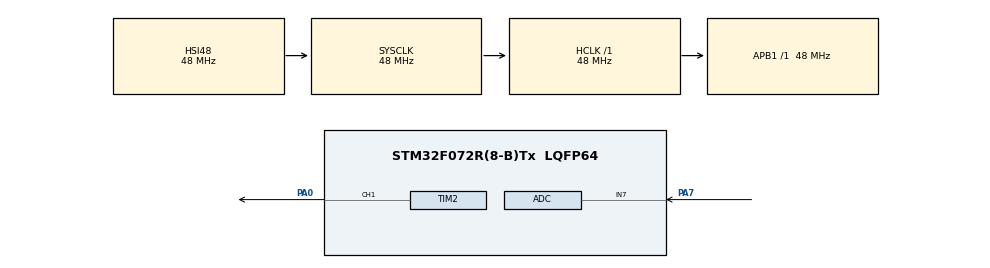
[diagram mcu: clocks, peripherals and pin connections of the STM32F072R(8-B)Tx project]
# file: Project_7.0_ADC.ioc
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ADC.SamplingTime=ADC_SAMPLETIME_1CYCLE_5
Dma.ADC.0.Direction=DMA_PERIPH_TO_MEMORY
Dma.ADC.0.Instance=DMA1_Channel1
Dma.ADC.0.MemDataAlignment=DMA_MDATAALIGN_HALFWORD
Dma.ADC.0.MemInc=DMA_MINC_ENABLE
Dma.ADC.0.Mode=DMA_NORMAL
Dma.ADC.0.PeriphDataAlignment=DMA_PDATAALIGN_HALFWORD
Dma.ADC.0.PeriphInc=DMA_PINC_DISABLE
Dma.ADC.0.Priority=DMA_PRIORITY_LOW
Dma.Request0=ADC
Mcu.Family=STM32F0
Mcu.Name=STM32F072R(8-B)Tx
Mcu.Package=LQFP64
NVIC.DMA1_Channel1_IRQn=true\:0\:0\:false\:false\:true\:false\:true\:true
PA0.Signal=S_TIM2_CH1_ETR
PA7.Mode=IN7
PA7.Signal=ADC_IN7
PF0-OSC_IN.Mode=HSE-External-Oscillator
PF0-OSC_IN.Signal=RCC_OSC_IN
PF1-OSC_OUT.Mode=HSE-External-Oscillator
PF1-OSC_OUT.Signal=RCC_OSC_OUT
ProjectManager.HeapSize=0x200
ProjectManager.StackSize=0x400
ProjectManager.TargetToolchain=STM32CubeIDE
RCC.AHBFreq_Value=48000000
RCC.APB1Freq_Value=48000000
RCC.APB1TimFreq_Value=48000000
RCC.HCLKFreq_Value=48000000
RCC.SYSCLKFreq_VALUE=48000000
RCC.SYSCLKSource=RCC_SYSCLKSOURCE_HSI48
SH.S_TIM2_CH1_ETR.0=TIM2_CH1,PWM Generation1 CH1
TIM2.AutoReloadPreload=TIM_AUTORELOAD_PRELOAD_ENABLE
TIM2.Channel-PWM\ Generation1\ CH1=TIM_CHANNEL_1
TIM2.Period=65535
VP_TIM2_VS_ClockSourceINT.Mode=Internal
board=custom

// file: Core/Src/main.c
/* USER CODE BEGIN Header */
/**
  ******************************************************************************
  * @file           : main.c
  * @brief          : Main program body
  ******************************************************************************
  * @attention
  *
  * Copyright (c) 2023 STMicroelectronics.
  * All rights reserved.
  *
  * This software is licensed under terms that can be found in the LICENSE file
  * in the root directory of this software component.
  * If no LICENSE file comes with this software, it is provided AS-IS.
  *
  ******************************************************************************
  */
/* USER CODE END Header */
#include "main.h"

/* USER CODE BEGIN Includes */
uint16_t AD_RES = 0;
uint16_t x = 0;
/* USER CODE END Includes */

ADC_HandleTypeDef hadc;
DMA_HandleTypeDef hdma_adc;

TIM_HandleTypeDef htim2;

void SystemClock_Config(void);
static void MX_GPIO_Init(void);
static void MX_DMA_Init(void);
static void MX_ADC_Init(void);
static void MX_TIM2_Init(void);

/* USER CODE BEGIN 0 */
HAL_ADC_ConvCpltCallback(ADC_HandleTypeDef* hadc){
	TIM2->CCR1 = (AD_RES<<4);

}
/* USER CODE END 0 */

int main(void)
{

  /* MCU Configuration--------------------------------------------------------*/

  /* Reset of all peripherals, Initializes the Flash interface and the Systick. */
  HAL_Init();

  /* Configure the system clock */
  SystemClock_Config();

  /* Initialize all configured peripherals */
  MX_GPIO_Init();
  MX_DMA_Init();
  MX_ADC_Init();
  MX_TIM2_Init();
  /* USER CODE BEGIN 2 */
  HAL_TIM_PWM_Start(&htim2, TIM_CHANNEL_1);
  HAL_ADCEx_Calibration_Start(&hadc);
  /* USER CODE END 2 */

  /* Infinite loop */
  while (1)
  {

    /* USER CODE BEGIN 3 */
      HAL_ADC_Start_DMA(&hadc, &AD_RES, 1);
      HAL_Delay(1);

  }
  /* USER CODE END 3 */
}

void SystemClock_Config(void)
{
  RCC_OscInitTypeDef RCC_OscInitStruct = {0};
  RCC_ClkInitTypeDef RCC_ClkInitStruct = {0};

  /** Initializes the RCC Oscillators according to the specified parameters
  * in the RCC_OscInitTypeDef structure.
  */
  RCC_OscInitStruct.OscillatorType = RCC_OSCILLATORTYPE_HSI14|RCC_OSCILLATORTYPE_HSI48;
  RCC_OscInitStruct.HSI48State = RCC_HSI48_ON;
  RCC_OscInitStruct.HSI14State = RCC_HSI14_ON;
  RCC_OscInitStruct.HSI14CalibrationValue = 16;
  RCC_OscInitStruct.PLL.PLLState = RCC_PLL_NONE;
  if (HAL_RCC_OscConfig(&RCC_OscInitStruct) != HAL_OK)
  {
    Error_Handler();
  }

  /** Initializes the CPU, AHB and APB buses clocks
  */
  RCC_ClkInitStruct.ClockType = RCC_CLOCKTYPE_HCLK|RCC_CLOCKTYPE_SYSCLK
                              |RCC_CLOCKTYPE_PCLK1;
  RCC_ClkInitStruct.SYSCLKSource = RCC_SYSCLKSOURCE_HSI48;
  RCC_ClkInitStruct.AHBCLKDivider = RCC_SYSCLK_DIV1;
  RCC_ClkInitStruct.APB1CLKDivider = RCC_HCLK_DIV1;

  if (HAL_RCC_ClockConfig(&RCC_ClkInitStruct, FLASH_LATENCY_1) != HAL_OK)
  {
    Error_Handler();
  }
}

static void MX_ADC_Init(void)
{

  ADC_ChannelConfTypeDef sConfig = {0};

  /** Configure the global features of the ADC (Clock, Resolution, Data Alignment and number of conversion)
  */
  hadc.Instance = ADC1;
  hadc.Init.ClockPrescaler = ADC_CLOCK_ASYNC_DIV1;
  hadc.Init.Resolution = ADC_RESOLUTION_12B;
  hadc.Init.DataAlign = ADC_DATAALIGN_RIGHT;
  hadc.Init.ScanConvMode = ADC_SCAN_DIRECTION_FORWARD;
  hadc.Init.EOCSelection = ADC_EOC_SINGLE_CONV;
  hadc.Init.LowPowerAutoWait = DISABLE;
  hadc.Init.LowPowerAutoPowerOff = DISABLE;
  hadc.Init.ContinuousConvMode = DISABLE;
  hadc.Init.DiscontinuousConvMode = DISABLE;
  hadc.Init.ExternalTrigConv = ADC_SOFTWARE_START;
  hadc.Init.ExternalTrigConvEdge = ADC_EXTERNALTRIGCONVEDGE_NONE;
  hadc.Init.DMAContinuousRequests = DISABLE;
  hadc.Init.Overrun = ADC_OVR_DATA_PRESERVED;
  if (HAL_ADC_Init(&hadc) != HAL_OK)
  {
    Error_Handler();
  }

  /** Configure for the selected ADC regular channel to be converted.
  */
  sConfig.Channel = ADC_CHANNEL_7;
  sConfig.Rank = ADC_RANK_CHANNEL_NUMBER;
  sConfig.SamplingTime = ADC_SAMPLETIME_1CYCLE_5;
  if (HAL_ADC_ConfigChannel(&hadc, &sConfig) != HAL_OK)
  {
    Error_Handler();
  }

}

static void MX_TIM2_Init(void)
{

  TIM_ClockConfigTypeDef sClockSourceConfig = {0};
  TIM_MasterConfigTypeDef sMasterConfig = {0};
  TIM_OC_InitTypeDef sConfigOC = {0};

  htim2.Instance = TIM2;
  htim2.Init.Prescaler = 0;
  htim2.Init.CounterMode = TIM_COUNTERMODE_UP;
  htim2.Init.Period = 65535;
  htim2.Init.ClockDivision = TIM_CLOCKDIVISION_DIV1;
  htim2.Init.AutoReloadPreload = TIM_AUTORELOAD_PRELOAD_ENABLE;
  if (HAL_TIM_Base_Init(&htim2) != HAL_OK)
  {
    Error_Handler();
  }
  sClockSourceConfig.ClockSource = TIM_CLOCKSOURCE_INTERNAL;
  if (HAL_TIM_ConfigClockSource(&htim2, &sClockSourceConfig) != HAL_OK)
  {
    Error_Handler();
  }
  if (HAL_TIM_PWM_Init(&htim2) != HAL_OK)
  {
    Error_Handler();
  }
  sMasterConfig.MasterOutputTrigger = TIM_TRGO_RESET;
  sMasterConfig.MasterSlaveMode = TIM_MASTERSLAVEMODE_DISABLE;
  if (HAL_TIMEx_MasterConfigSynchronization(&htim2, &sMasterConfig) != HAL_OK)
  {
    Error_Handler();
  }
  sConfigOC.OCMode = TIM_OCMODE_PWM1;
  sConfigOC.Pulse = 0;
  sConfigOC.OCPolarity = TIM_OCPOLARITY_HIGH;
  sConfigOC.OCFastMode = TIM_OCFAST_DISABLE;
  if (HAL_TIM_PWM_ConfigChannel(&htim2, &sConfigOC, TIM_CHANNEL_1) != HAL_OK)
  {
    Error_Handler();
  }
  HAL_TIM_MspPostInit(&htim2);

}

static void MX_DMA_Init(void)
{

  /* DMA controller clock enable */
  __HAL_RCC_DMA1_CLK_ENABLE();

  /* DMA interrupt init */
  /* DMA1_Channel1_IRQn interrupt configuration */
  HAL_NVIC_SetPriority(DMA1_Channel1_IRQn, 0, 0);
  HAL_NVIC_EnableIRQ(DMA1_Channel1_IRQn);

}

static void MX_GPIO_Init(void)
{

  /* GPIO Ports Clock Enable */
  __HAL_RCC_GPIOF_CLK_ENABLE();
  __HAL_RCC_GPIOA_CLK_ENABLE();

}

void Error_Handler(void)
{
  __disable_irq();
  while (1)
  {
  }
}
